AUTOSAR XML (schema 314)
package /ComponentType
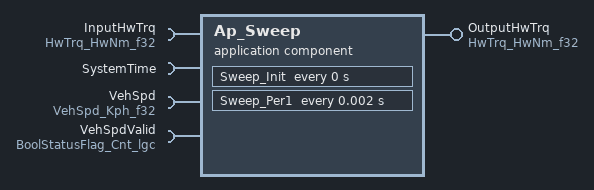
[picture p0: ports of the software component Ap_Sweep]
  application software component type Ap_Sweep
    provide port OutputHwTrq: unqueued-sender-com-spec{data-element=HwNm_f32, can-invalidate=false, init-value=D_ZERO_ULS_F32}, provided-interface=HwTrq_HwNm_f32
    4 x require port:
      InputHwTrq: unqueued-receiver-com-spec{data-element=HwNm_f32, init-value=D_ZERO_ULS_F32}, required-interface=HwTrq_HwNm_f32
      SystemTime: required-interface=SystemTime
        required-com-specs:
          DtrmnElapsedTime_mS_u16
          DtrmnElapsedTime_mS_u32
          DtrmnElapsedTime_uS_u16
          DtrmnElapsedTime_uS_u32
          GetSystemTime_mS_u32
          GetSystemTime_uS_u32
      VehSpd: unqueued-receiver-com-spec{data-element=Kph_f32, init-value=D_ZERO_ULS_F32}, required-interface=VehSpd_Kph_f32
      VehSpdValid: unqueued-receiver-com-spec{data-element=Cnt_lgc, init-value=D_FALSE_CNT_LGC}, required-interface=BoolStatusFlag_Cnt_lgc
  internal behavior Ap_Sweep_InternalBehavior: component=Ap_Sweep
    timing event Sweep_InitEvent: start-on-event=Sweep_Init, period=0
    timing event TMT_Sweep_Per1: start-on-event=Sweep_Per1, period=0.002
    port-api-options:
      enable-take-address=false, indirect-api=false, port=InputHwTrq
      enable-take-address=false, indirect-api=false, port=OutputHwTrq
      enable-take-address=false, indirect-api=false, port=SystemTime
      enable-take-address=false, indirect-api=false, port=VehSpd
      enable-take-address=false, indirect-api=false, port=VehSpdValid
    runnable Sweep_Init
    runnable Sweep_Per1
      data read access READ_InputHwTrq_HwNm_f32: data-element=InputHwTrq.HwNm_f32
      data read access READ_VehSpd_Kph_f32: data-element=VehSpd.Kph_f32
      data read access READ_VehSpdValid_Cnt_lgc: data-element=VehSpdValid.Cnt_lgc
      data write access WRITE_OutputHwTrq_HwNm_f32: data-element=OutputHwTrq.HwNm_f32
      sync call SC_SystemTime_DtrmnElapsedTime_mS_u16: operation=SystemTime.DtrmnElapsedTime_mS_u16, timeout=0
      sync call SC_SystemTime_GetSystemTime_mS_u32: operation=SystemTime.GetSystemTime_mS_u32, timeout=0
  swc implementation Ap_Sweep_Implementation: behavior=Ap_Sweep_InternalBehavior
    code-descriptors:
      code Code: type=SRC
